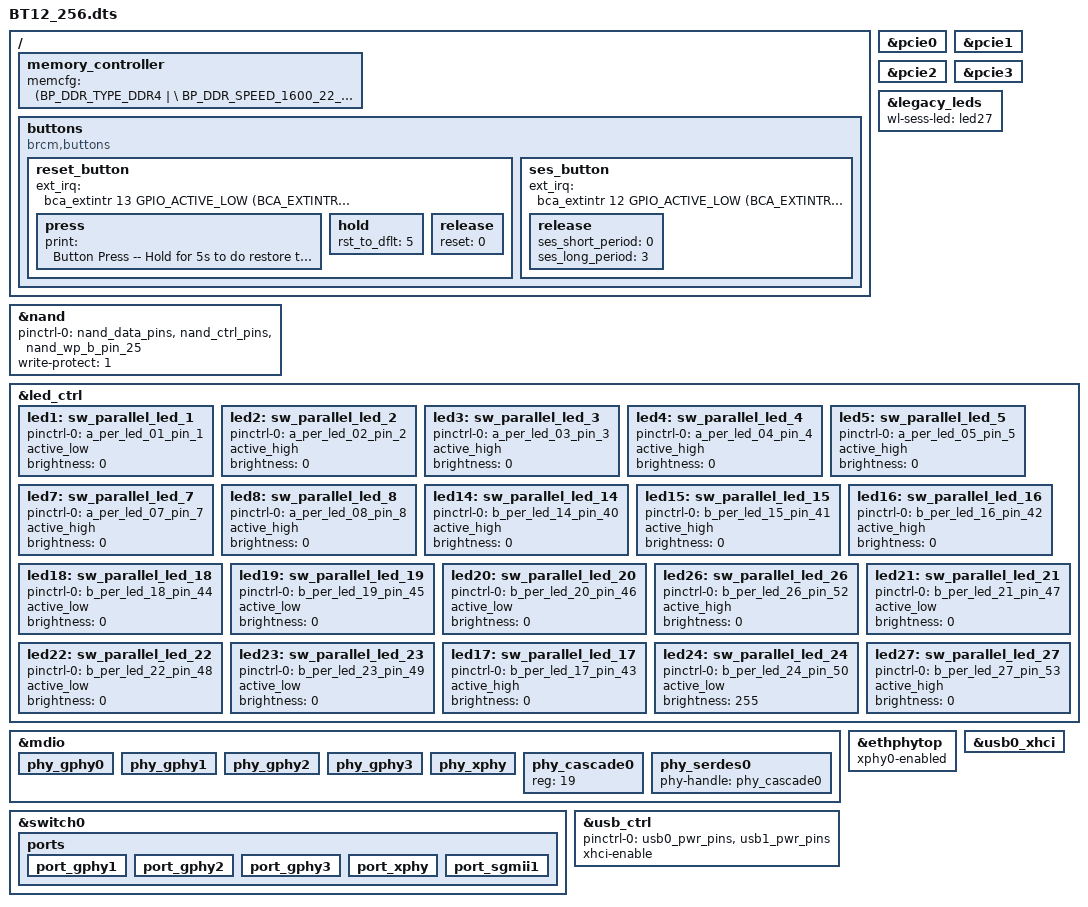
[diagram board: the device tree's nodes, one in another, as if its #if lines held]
#include "6813.dtsi"

/ {
	memory_controller {
		memcfg = <(BP_DDR_TYPE_DDR4       | \
			BP_DDR_SPEED_1600_22_22_22    | \
			BP_DDR_TOTAL_SIZE_1024MB      | \
			BP_DDR_DEVICE_WIDTH_16        | \
			BP_DDR_TOTAL_WIDTH_16BIT      | \
			BP_DDR_TEMP_EXTENDED_ASR      | \
			BP_DDR_SSC_CONFIG_1)>;
	};

    buttons: buttons {
        compatible = "brcm,buttons";
        reset_button {
            ext_irq = <&bca_extintr 13 GPIO_ACTIVE_LOW (BCA_EXTINTR_TYPE_LOW_LEVEL | BCA_EXTINTR_TYPE_SENSE_EDGE)>;
            press {
                print = "Button Press -- Hold for 5s to do restore to default";
            };
            hold {
                rst_to_dflt = <5>;
            };
            release {
                reset = <0>;
            };
        };
        ses_button {
            ext_irq = <&bca_extintr 12 GPIO_ACTIVE_LOW (BCA_EXTINTR_TYPE_LOW_LEVEL | BCA_EXTINTR_TYPE_SENSE_EDGE)>;
            release {
                ses_short_period = <0>;
                ses_long_period = <3>;
            };
        };
    };
};

&nand {
	pinctrl-0 = <&nand_data_pins &nand_ctrl_pins &nand_wp_b_pin_25>;
	write-protect = <1>;
	status = "okay";
};

#if defined(CONFIG_BCM_PCIE_HCD) || defined(CONFIG_BCM_PCIE_HCD_MODULE)
&pcie0 {
	status = "okay";
};
&pcie1 {
	status = "okay";
};
&pcie2 {
	status = "okay";
};
&pcie3 {
	status = "okay";
};
#endif //#if defined(CONFIG_BCM_PCIE_HCD) || defined(CONFIG_BCM_PCIE_HCD_MODULE)

&legacy_leds {
    wl-sess-led = <&led27>;
};

&led_ctrl {
    status="okay";

	/* CLED */
    /* LAN_LED */
    led1:sw_parallel_led_1 {
		pinctrl-0 = <&a_per_led_01_pin_1>;
        active_low;
        status="okay";
        brightness = <0>;
	};

    /* LED_1A_R */
    led2: sw_parallel_led_2 {
		pinctrl-0 = <&a_per_led_02_pin_2>;
        active_high;
        status="okay";
        brightness = <0>;
	};
    /* LED_1A_B */
    led3: sw_parallel_led_3 {
		pinctrl-0 = <&a_per_led_03_pin_3>;
        active_high;
        status="okay";
        brightness = <0>;
	};
    /* LED_1A_G */
    led4: sw_parallel_led_4 {
		pinctrl-0 = <&a_per_led_04_pin_4>;
        active_high;
        status="okay";
        brightness = <0>;
	};

    /* LED_1B_R */
    led5: sw_parallel_led_5 {
		pinctrl-0 = <&a_per_led_05_pin_5>;
        active_high;
        status="okay";
        brightness = <0>;
	};
    /* LED_1B_B */
    led7: sw_parallel_led_7 {
		pinctrl-0 = <&a_per_led_07_pin_7>;
        active_high;
        status="okay";
        brightness = <0>;
	};
    /* LED_1B_G */
    led8: sw_parallel_led_8 {
		pinctrl-0 = <&a_per_led_08_pin_8>;
        active_high;
        status="okay";
        brightness = <0>;
	};

    /* LED_1C_R */
    led14: sw_parallel_led_14 {
		pinctrl-0 = <&b_per_led_14_pin_40>;
        active_high;
        status="okay";
        brightness = <0>;
	};
    /* LED_1C_B */
    led15: sw_parallel_led_15 {
		pinctrl-0 = <&b_per_led_15_pin_41>;
        active_high;
        status="okay";
        brightness = <0>;
	};
    /* LED_1C_G */
    led16: sw_parallel_led_16 {
		pinctrl-0 = <&b_per_led_16_pin_42>;
        active_high;
        status="okay";
        brightness = <0>;
	};

    /* WAN_LED_R */
    led18: sw_parallel_led_18 {
		pinctrl-0 = <&b_per_led_18_pin_44>;
        active_low;
        status="okay";
        brightness = <0>;
	};
    /* WAN_LED_G */
    led19: sw_parallel_led_19 {
		pinctrl-0 = <&b_per_led_19_pin_45>;
        active_low;
        status="okay";
        brightness = <0>;
	};
    /* WAN_LED_B */
    led20: sw_parallel_led_20 {
		pinctrl-0 = <&b_per_led_20_pin_46>;
        active_low;
        status="okay";
        brightness = <0>;
	};
    /* WAN_LED_WHITE */
    led26: sw_parallel_led_26 {
		pinctrl-0 = <&b_per_led_26_pin_52>;
        active_high;
        status="okay";
        brightness = <0>;
	};

    /* 10GE_LED_R */
    led21: sw_parallel_led_21 {
		pinctrl-0 = <&b_per_led_21_pin_47>;
        active_low;
        status="okay";
        brightness = <0>;
	};
    /* 10GE_LED_G */
    led22: sw_parallel_led_22 {
		pinctrl-0 = <&b_per_led_22_pin_48>;
        active_low;
        status="okay";
        brightness = <0>;
	};
    /* 10GE_LED_B */
    led23: sw_parallel_led_23 {
		pinctrl-0 = <&b_per_led_23_pin_49>;
        active_low;
        status="okay";
        brightness = <0>;
	};
    /* 10G_LED_WHITE */
    led17: sw_parallel_led_17 {
		pinctrl-0 = <&b_per_led_17_pin_43>;
        active_high;
        status="okay";
        brightness = <0>;
	};

    /* POWER_LED */
    led24: sw_parallel_led_24 {
		pinctrl-0 = <&b_per_led_24_pin_50>;
        active_low;
        status="okay";
        brightness = <255>;
	};

    /* WPS_LED */
    led27: sw_parallel_led_27 {
        pinctrl-0=<&b_per_led_27_pin_53>;
        active_high;
        status = "okay";
        brightness = <0>;
    };
};

/* For AURA72UB0, NP for now
&i2c1 {
	pinctrl-names = "default";
	pinctrl-0 = <&i2c1_sclk_pin_14 &i2c1_sdata_pin_15>;
	status = "okay";
};
*/

&mdio {
    /* Port PHY mapping:
        port_gphy0 <----> phy_gphy0
        port_gphy1 <----> phy_gphy1
        port_gphy2 <----> phy_gphy2
        port_gphy3 <----> phy_gphy3
        port_xphy <-----> phy_xphy      - Internal 10G PHY
        port_sgmii1 <---> phy_serdes0   - BCM84891L
        port_sgmii2 <---> phy_serdes1   - BCM84891L
     */
	phy_gphy0 {
		status = "okay";
	};

	phy_gphy1 {
		status = "okay";
	};

	phy_gphy2 {
		status = "okay";
	};

	phy_gphy3 {
		status = "okay";
	};

	phy_xphy {
		status = "okay";
	};

    phy_cascade0 {
        reg = <19>;
		status = "okay";
	};

	phy_serdes0 {
		phy-handle = <&phy_cascade0>;
		status = "okay";
	};

    /* Disable SGMII-2/BCM84891L, not installed
    phy_cascade1 {
        reg = <21>;
		status = "okay";
	};

	phy_serdes1 {
		phy-handle = <&phy_cascade1>;
		status = "okay";
	};
	*/
};

&ethphytop {
    xphy0-enabled;
    status = "okay";
};

&switch0 {
	ports {
		/*
		port_gphy0 {
			status = "okay";
		};
		*/

		port_gphy1 {
			status = "okay";
		};

		port_gphy2 {
			status = "okay";
		};

		port_gphy3 {
			status = "okay";
		};

		port_xphy {
			status = "okay";
		};

		port_sgmii1 {
			status = "okay";
		};

        /* Disable SGMII-1/BCM84891L, not installed
		port_sgmii2 {
			status = "okay";
		};
		*/
	};
};

&usb_ctrl {
	pinctrl-names = "default";
	pinctrl-0 = <&usb0_pwr_pins &usb1_pwr_pins>;
	status = "okay";
	xhci-enable;
};
&usb0_xhci {
	status = "okay";
};
